VERSION ""

NS_ :

BS_:

BU_: CH10x

BO_ 1672 Pressure: 4 Vector__XXX
 SG_ Pressure : 0|32@1- (1,0) [0|0] "Pa" Vector__XXX

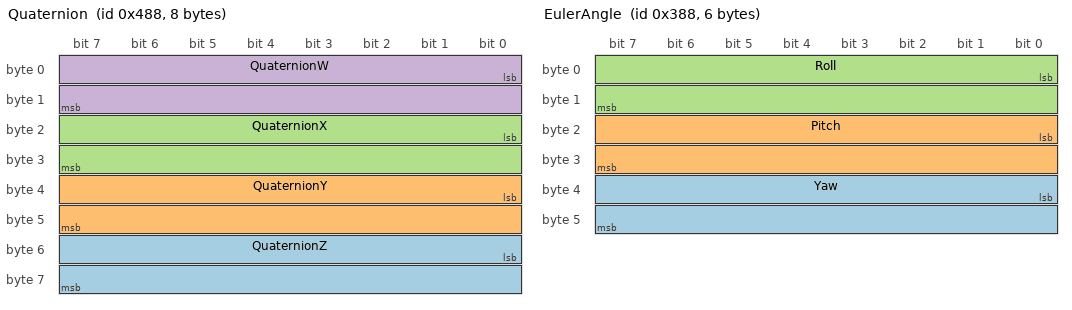
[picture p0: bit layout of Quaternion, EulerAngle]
BO_ 1160 Quaternion: 8 Vector__XXX
 SG_ QuaternionZ : 48|16@1- (0.0001,0) [0|0] "" Vector__XXX
 SG_ QuaternionY : 32|16@1- (0.0001,0) [0|0] "" Vector__XXX
 SG_ QuaternionX : 16|16@1- (0.0001,0) [0|0] "" Vector__XXX
 SG_ QuaternionW : 0|16@1- (0.0001,0) [0|0] "" Vector__XXX

BO_ 904 EulerAngle: 6 Vector__XXX
 SG_ Yaw : 32|16@1- (0.01,0) [0|0] "deg" Vector__XXX
 SG_ Pitch : 16|16@1- (0.01,0) [0|0] "deg" Vector__XXX
 SG_ Roll : 0|16@1- (0.01,0) [0|0] "deg" Vector__XXX

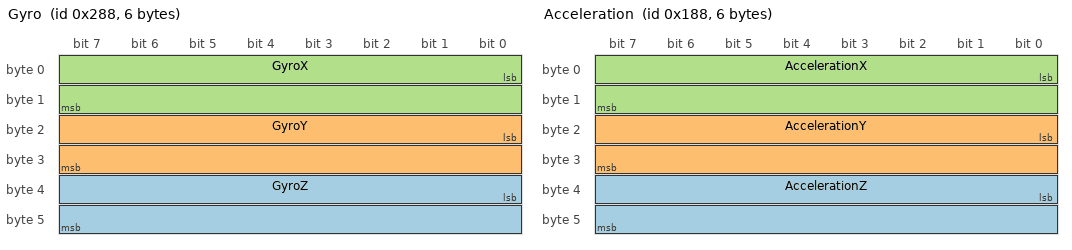
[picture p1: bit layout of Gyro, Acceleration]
BO_ 648 Gyro: 6 Vector__XXX
 SG_ GyroZ : 32|16@1- (0.1,0) [0|0] "deg/s" Vector__XXX
 SG_ GyroY : 16|16@1- (0.1,0) [0|0] "deg/s" Vector__XXX
 SG_ GyroX : 0|16@1- (0.1,0) [0|0] "deg/s" Vector__XXX

BO_ 392 Acceleration: 6 CH10x
 SG_ AccelerationZ : 32|16@1- (0.001,0) [0|0] "G" Vector__XXX
 SG_ AccelerationY : 16|16@1- (0.001,0) [0|0] "G" Vector__XXX
 SG_ AccelerationX : 0|16@1- (0.001,0) [0|0] "G" Vector__XXX

BA_DEF_ SG_  "GenSigSendType" ENUM  "Cyclic","OnWrite","OnWriteWithRepetition","OnChange","OnChangeWithRepetition","IfActive","IfActiveWithRepetition","NoSigSendType";
BA_DEF_ BO_  "GenMsgSendType" ENUM  "Cyclic","not_used","not_used","not_used","not_used","Cyclic","not_used","IfActive","NoMsgSendType";
BA_DEF_ BU_  "NmStationAddress" HEX 0 0;
BA_DEF_  "DBName" STRING ;
BA_DEF_  "BusType" STRING ;
BA_DEF_DEF_  "GenSigSendType" "Cyclic";
BA_DEF_DEF_  "GenMsgSendType" "NoMsgSendType";
BA_DEF_DEF_  "NmStationAddress" 0;
BA_DEF_DEF_  "DBName" "";
BA_DEF_DEF_  "BusType" "CAN";
BA_ "DBName" "CH10x_CANopen";
BA_ "NmStationAddress" BU_ CH10x 8;
